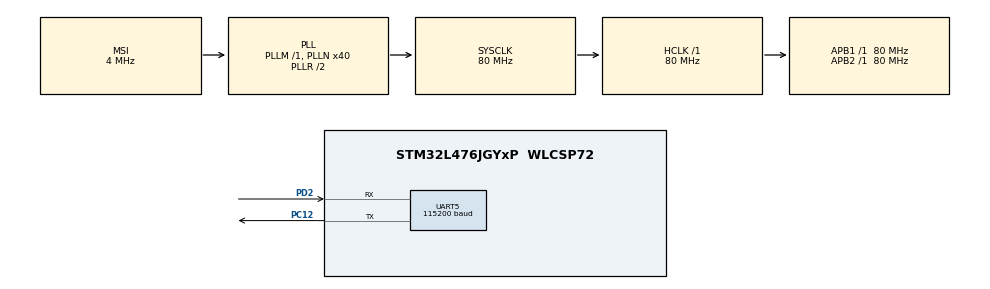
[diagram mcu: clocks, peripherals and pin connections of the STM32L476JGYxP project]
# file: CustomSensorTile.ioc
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Mcu.Family=STM32L4
Mcu.Name=STM32L476JGYxP
Mcu.Package=WLCSP72
NVIC.PriorityGroup=NVIC_PRIORITYGROUP_4
NVIC.UART5_IRQn=true\:0\:0\:false\:false\:true\:true\:true\:true
PC12.Mode=Asynchronous
PC12.Signal=UART5_TX
PD2.Mode=Asynchronous
PD2.Signal=UART5_RX
ProjectManager.HeapSize=0x200
ProjectManager.StackSize=0x400
ProjectManager.TargetToolchain=STM32CubeIDE
RCC.AHBFreq_Value=80000000
RCC.APB1Freq_Value=80000000
RCC.APB1TimFreq_Value=80000000
RCC.APB2Freq_Value=80000000
RCC.APB2TimFreq_Value=80000000
RCC.CortexFreq_Value=80000000
RCC.HCLKFreq_Value=80000000
RCC.HSE_VALUE=8000000
RCC.HSI_VALUE=16000000
RCC.LSE_VALUE=32768
RCC.MSI_VALUE=4000000
RCC.PLLN=40
RCC.SYSCLKFreq_VALUE=80000000
RCC.SYSCLKSource=RCC_SYSCLKSOURCE_PLLCLK
RCC.VCOOutputFreq_Value=160000000
UART5.BaudRate=115200
board=custom

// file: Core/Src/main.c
/* USER CODE BEGIN Header */
/**
  ******************************************************************************
  * @file           : main.c
  * @brief          : Main program body
  ******************************************************************************
  * @attention
  *
  * Copyright (c) 2023 STMicroelectronics.
  * All rights reserved.
  *
  * This software is licensed under terms that can be found in the LICENSE file
  * in the root directory of this software component.
  * If no LICENSE file comes with this software, it is provided AS-IS.
  *
  ******************************************************************************
  */
/* USER CODE END Header */
#include "main.h"
#include "usart.h"
#include "gpio.h"

/* USER CODE BEGIN Includes */
#include "dynamixel.h"
#include "math.h"
/* USER CODE END Includes */

/* USER CODE BEGIN PV */
uint8_t DXL_IDS[]= {10,11};
uint8_t num_motors = 2;
/* USER CODE END PV */

void SystemClock_Config(void);

int main(void)
{

  /* MCU Configuration--------------------------------------------------------*/

  /* Reset of all peripherals, Initializes the Flash interface and the Systick. */
  HAL_Init();

  /* Configure the system clock */
  SystemClock_Config();

  /* Initialize all configured peripherals */
  MX_GPIO_Init();
  MX_UART5_Init();

  /* Infinite loop */
  /* USER CODE BEGIN WHILE */

  for(uint8_t i = 0; i < num_motors; i++)
  {
	  dyna_init(DXL_IDS[i]);
  }

  uint16_t loop_cnt = 0;
  int16_t current = 0;
  while (1)
  {
	current = 300*sin(2*M_PI*loop_cnt*0.01*5);
	sync_write(current, current);
    loop_cnt++;
    HAL_Delay(10);

    /* USER CODE END WHILE */

  }
}

void SystemClock_Config(void)
{
  RCC_OscInitTypeDef RCC_OscInitStruct = {0};
  RCC_ClkInitTypeDef RCC_ClkInitStruct = {0};

  /** Configure the main internal regulator output voltage
  */
  if (HAL_PWREx_ControlVoltageScaling(PWR_REGULATOR_VOLTAGE_SCALE1) != HAL_OK)
  {
    Error_Handler();
  }

  /** Initializes the RCC Oscillators according to the specified parameters
  * in the RCC_OscInitTypeDef structure.
  */
  RCC_OscInitStruct.OscillatorType = RCC_OSCILLATORTYPE_MSI;
  RCC_OscInitStruct.MSIState = RCC_MSI_ON;
  RCC_OscInitStruct.MSICalibrationValue = 0;
  RCC_OscInitStruct.MSIClockRange = RCC_MSIRANGE_6;
  RCC_OscInitStruct.PLL.PLLState = RCC_PLL_ON;
  RCC_OscInitStruct.PLL.PLLSource = RCC_PLLSOURCE_MSI;
  RCC_OscInitStruct.PLL.PLLM = 1;
  RCC_OscInitStruct.PLL.PLLN = 40;
  RCC_OscInitStruct.PLL.PLLP = RCC_PLLP_DIV7;
  RCC_OscInitStruct.PLL.PLLQ = RCC_PLLQ_DIV2;
  RCC_OscInitStruct.PLL.PLLR = RCC_PLLR_DIV2;
  if (HAL_RCC_OscConfig(&RCC_OscInitStruct) != HAL_OK)
  {
    Error_Handler();
  }

  /** Initializes the CPU, AHB and APB buses clocks
  */
  RCC_ClkInitStruct.ClockType = RCC_CLOCKTYPE_HCLK|RCC_CLOCKTYPE_SYSCLK
                              |RCC_CLOCKTYPE_PCLK1|RCC_CLOCKTYPE_PCLK2;
  RCC_ClkInitStruct.SYSCLKSource = RCC_SYSCLKSOURCE_PLLCLK;
  RCC_ClkInitStruct.AHBCLKDivider = RCC_SYSCLK_DIV1;
  RCC_ClkInitStruct.APB1CLKDivider = RCC_HCLK_DIV1;
  RCC_ClkInitStruct.APB2CLKDivider = RCC_HCLK_DIV1;

  if (HAL_RCC_ClockConfig(&RCC_ClkInitStruct, FLASH_LATENCY_4) != HAL_OK)
  {
    Error_Handler();
  }
}

void Error_Handler(void)
{
  __disable_irq();
  while (1)
  {
  }
}
